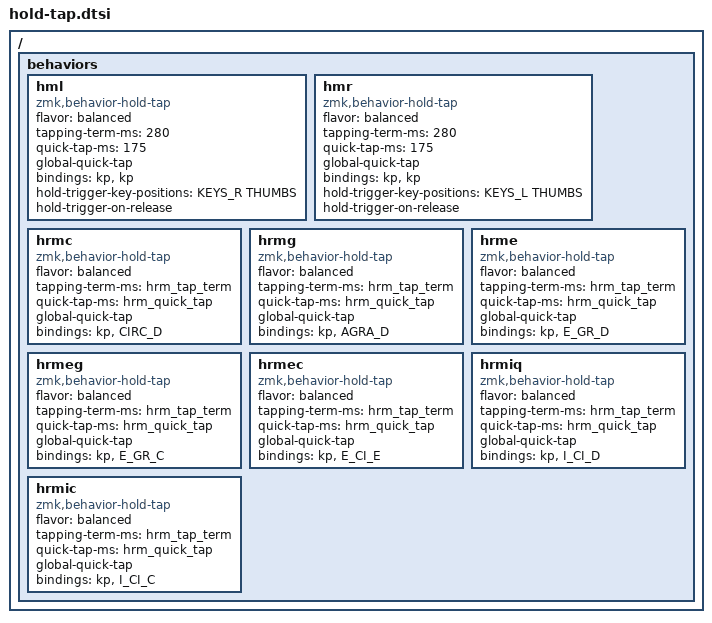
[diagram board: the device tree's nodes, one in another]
#include <behaviors.dtsi>
#include <dt-bindings/zmk/keys.h>
#include "zmk-helpers/helper.h"
#include "zmk-helpers/key-labels/36.h"
#include "../layouts/canadian-multilingual-standard.dtsi"
#include "../config/constants.h"

/* Home Row Mods */
#define KEYS_L LT0 LT1 LT2 LT3 LT4 LM0 LM1 LM2 LM3 LM4 LB0 LB1 LB2 LB3 LB4  // left-hand keys
#define KEYS_R RT0 RT1 RT2 RT3 RT4 RM0 RM1 RM2 RM3 RM4 RB0 RB1 RB2 RB3 RB4  // right-hand keys
#define THUMBS LH2 LH1 LH0 RH0 RH1 RH2 // thumb keys

#define hrm_tap_term 150
#define hrm_quick_tap 125

/* Timerless Home Row Mods */
/* https://github.com/urob/zmk-config#timeless-homerow-mods */

/* left-hand HRMs */
ZMK_HOLD_TAP(hml,
    flavor = "balanced";
    tapping-term-ms = <280>;
    quick-tap-ms = <175>;
    global-quick-tap;
    bindings = <&kp>, <&kp>;
    hold-trigger-key-positions = <KEYS_R THUMBS>;
    hold-trigger-on-release;
)

/* right-hand HRMs */
ZMK_HOLD_TAP(hmr,
    flavor = "balanced";
    tapping-term-ms = <280>;
    quick-tap-ms = <175>;
    global-quick-tap;
    bindings = <&kp>, <&kp>;
    hold-trigger-key-positions = <KEYS_L THUMBS>;
    hold-trigger-on-release;
)

// homerow mods for circumflex
ZMK_HOLD_TAP(hrmc,
    flavor = "balanced";
    tapping-term-ms = <hrm_tap_term>;
    quick-tap-ms = <hrm_quick_tap>;
    global-quick-tap;
    bindings = <&kp>, <&CIRC_D>;
)

// homerow mods for grave
ZMK_HOLD_TAP(hrmg,
    flavor = "balanced";
    tapping-term-ms = <hrm_tap_term>;
    quick-tap-ms = <hrm_quick_tap>;
    global-quick-tap;
    bindings = <&kp>, <&AGRA_D>;
)

// homerow mods for è
ZMK_HOLD_TAP(hrme,
    flavor = "balanced";
    tapping-term-ms = <hrm_tap_term>;
    quick-tap-ms = <hrm_quick_tap>;
    global-quick-tap;
    bindings = <&kp>, <&E_GR_D>;
)

// homerow mods for è
ZMK_HOLD_TAP(hrmeg,
    flavor = "balanced";
    tapping-term-ms = <hrm_tap_term>;
    quick-tap-ms = <hrm_quick_tap>;
    global-quick-tap;
    bindings = <&kp>, <&E_GR_C>;
)

// homerow mods for ê
ZMK_HOLD_TAP(hrmec,
    flavor = "balanced";
    tapping-term-ms = <hrm_tap_term>;
    quick-tap-ms = <hrm_quick_tap>;
    global-quick-tap;
    bindings = <&kp>, <&E_CI_E>;
)

// homerow mods for î (QWERTY)
ZMK_HOLD_TAP(hrmiq,
    flavor = "balanced";
    tapping-term-ms = <hrm_tap_term>;
    quick-tap-ms = <hrm_quick_tap>;
    global-quick-tap;
    bindings = <&kp>, <&I_CI_D>;
)

// homerow mods for î (Colemak)
ZMK_HOLD_TAP(hrmic,
    flavor = "balanced";
    tapping-term-ms = <hrm_tap_term>;
    quick-tap-ms = <hrm_quick_tap>;
    global-quick-tap;
    bindings = <&kp>, <&I_CI_C>;
)
